# ERRORS register map
Registers are 32-bit, read-write, no defined reset value unless marked. A register's access mark holds for its fields unless they carry their own. Offsets are from the block's base; lines under a group give offsets from that group; [hi:lo] are bit positions; {n}, {i} and the like mark numbered series; 'fields as' and 'values as' point back to an identical list; <NAME> marks a mode.

## Memory map
0x40000000 ...
0x40001000 B

## ...
Base 0x40000000
0x00 R

## B
Base 0x40001000
0x00 -
0x04 ?
0x20 G (__ view)
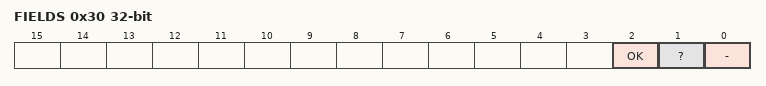
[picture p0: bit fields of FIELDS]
0x30 FIELDS
  [2] OK, [1] ?, [0] -
0x100 _ group
  0x00 X
